# GD32E511_512 register map
File version: 1.0
CPU: CM33 r0p4, little endian, MPU, FPU, 4 interrupt priority bits
Registers are 32-bit, read-write, reset 0x0 unless marked. A register's access mark holds for its fields unless they carry their own. Offsets are from the block's base; [hi:lo] are bit positions; {n}, {i} and the like mark numbered series.

## FWDGT — free watchdog timer
Base 0x40003000
0x00 CTL wo — Control register
  [15:0] CMD — Key value
0x04 PSC — Prescaler register
  [2:0] PSC — Prescaler divider
0x08 RLD reset 0xFFF — Reload register
  [11:0] RLD — Watchdog counter reload value
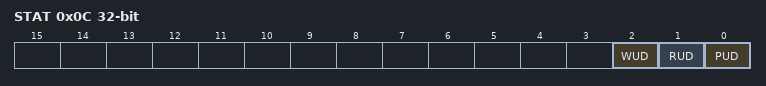
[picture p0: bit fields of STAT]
0x0C STAT ro — Status register
  [2] WUD — Watchdog counter window value update
  [1] RUD — Watchdog counter reload value update
  [0] PUD — Watchdog prescaler value update
0x10 WND reset 0xFFF — Window register
  [11:0] WND — Watchdog counter window value

## GPIOA — General-purpose I / O
Base 0x48000000
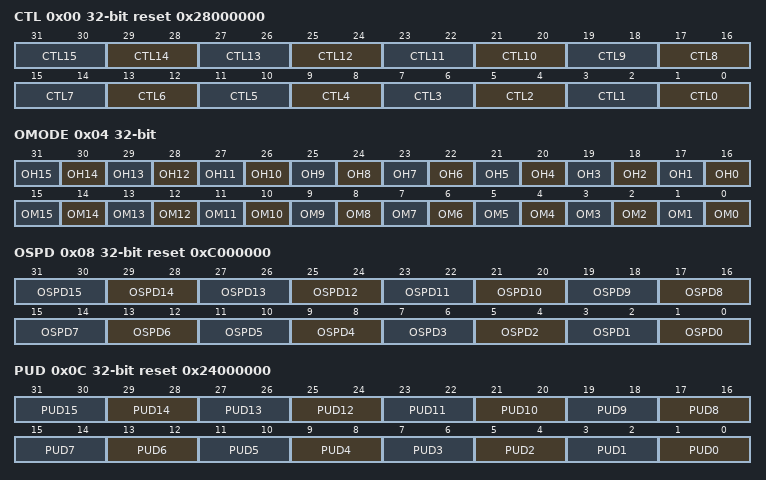
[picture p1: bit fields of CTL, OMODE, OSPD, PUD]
0x00 CTL reset 0x28000000 — Port control register
  [2n+1:2n] CTL{n} (n=0..15) — Pin {n} configuration bits
0x04 OMODE — Port output mode register
  [n+16] OH{n} (n=0..15) — Pin {n} output hold enable bit
  [n] OM{n} (n=0..15) — Pin {n} output mode bit
0x08 OSPD reset 0xC000000 — Port output speed register
  [2n+1:2n] OSPD{n} (n=0..15) — Pin {n} output max speed bits
0x0C PUD reset 0x24000000 — Port pull-up/down register
  [2n+1:2n] PUD{n} (n=0..15) — Pin {n} pull-up or pull-down bits
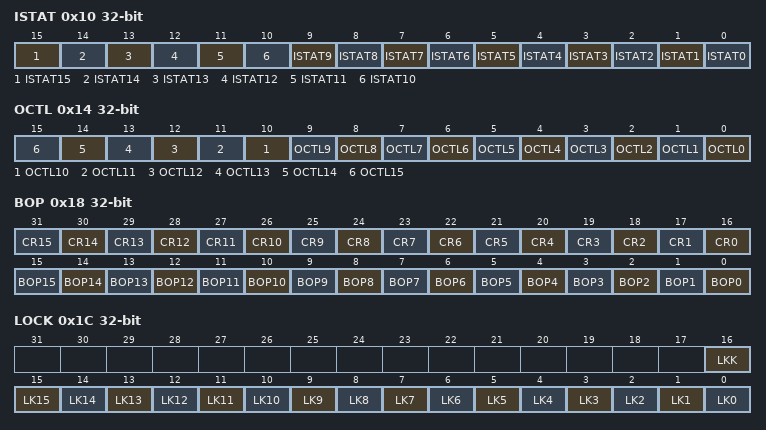
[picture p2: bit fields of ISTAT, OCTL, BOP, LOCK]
0x10 ISTAT ro — Port input status register
  [15] ISTAT15 — Port input status (y=15)
  [14] ISTAT14 — Port input status (y=14)
  [13] ISTAT13 — Port input status (y=13)
  [12] ISTAT12 — Port input status (y=12)
  [11] ISTAT11 — Port input status (y=11)
  [10] ISTAT10 — Port input status (y=10)
  [9] ISTAT9 — Port input status (y=9)
  [8] ISTAT8 — Port input status (y=8)
  [7] ISTAT7 — Port input status (y=7)
  [6] ISTAT6 — Port input status (y=6)
  [5] ISTAT5 — Port input status (y=5)
  [4] ISTAT4 — Port input status (y=4)
  [3] ISTAT3 — Port input status (y=3)
  [2] ISTAT2 — Port input status (y=2)
  [1] ISTAT1 — Port input status (y=1)
  [0] ISTAT0 — Port input status (y=0)
0x14 OCTL — Port output control register
  [n] OCTL{n} (n=0..15) — Port output control {n}
0x18 BOP wo — Port bit operate register
  [n+16] CR{n} (n=0..15) — Port clear bit {n}
  [n] BOP{n} (n=0..15) — Port set bit {n}
0x1C LOCK — Port configuration lock register
  [16] LKK — Lock key
  [n] LK{n} (n=0..15) — Port lock bit {n}
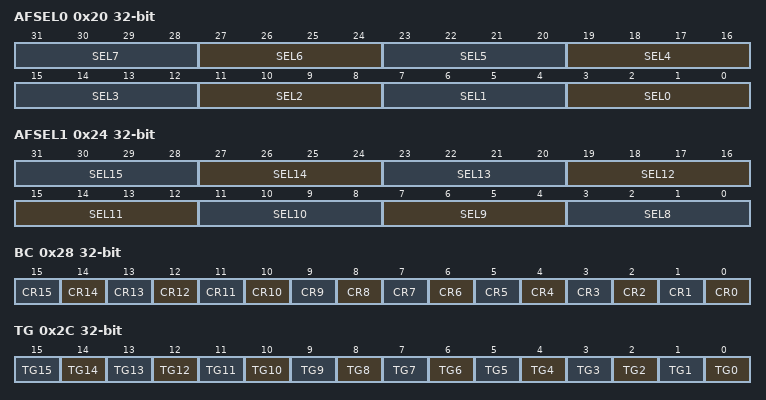
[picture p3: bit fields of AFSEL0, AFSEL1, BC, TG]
0x20 AFSEL0 — Alternate function selected register 0
  [4n+3:4n] SEL{n} (n=0..7) — Pin {n} alternate function selected
0x24 AFSEL1 — Alternate function selected register 1
  [4n-29:4n-32] SEL{n} (n=12..15) — Pin {n} alternate function selected
  [15:12] SEL11 — Pin 1 alternate function selected
  [11:8] SEL10 — Pin 10 alternate function selected
  [7:4] SEL9 — Pin 9 alternate function selected
  [3:0] SEL8 — Pin 8 alternate function selected
0x28 BC wo — Bit clear register
  [n] CR{n} (n=0..15) — Port clear bit {n}
0x2C TG wo — Port bit toggle register
  [n] TG{n} (n=0..15) — Port toggle bit {n}

## GPIOB — General-purpose I / O
Base 0x48000400
Same registers: GPIOC 0x48000800, GPIOD 0x48000C00, GPIOE 0x48001000, GPIOF 0x48001400, GPIOG 0x48001800
Registers as GPIOA; these are added or differ:
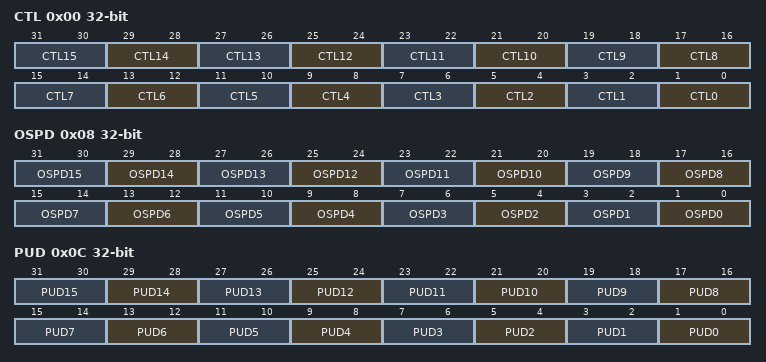
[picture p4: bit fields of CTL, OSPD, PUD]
0x00 CTL — Port control register
  [2n+1:2n] CTL{n} (n=0..15) — Pin {n} configuration bits
0x08 OSPD — Port output speed register
  [2n+1:2n] OSPD{n} (n=0..15) — Pin {n} output max speed bits
0x0C PUD — Port pull-up/down register
  [2n+1:2n] PUD{n} (n=0..15) — Pin {n} pull-up or pull-down bits

## NVIC — Nested Vectored Interrupt Controller
Base 0xE000E100
{0x0+4i} ISER{i} (i=0..15) — Interrupt Set Enable Register
  [31:0] SETENA
0x80 ICER0 — Interrupt Clear Enable Register
  [31:0] CLRENA
0x84 ICER1 — Interrupt Clear Enable Register
  [31:0] CLRENA
{0x84+4i} ICER{i} (i=2..15) — Interrupt Clear Enable Register
  [31:0] CLRENA
{0x100+4i} ISPR{i} (i=0..15) — Interrupt Set-Pending Register
  [31:0] SETPEND
{0x180+4i} ICPR{i} (i=0..15) — Interrupt Clear-Pending Register
  [31:0] CLRPEND
{0x200+4i} IABR{i} (i=0..15) — Interrupt Active bit Register
  [31:0] IABR
{0x280+4i} ITNS{i} (i=0..15) — Interrupt Active bit Register
  [31:0] ITNS
{0x300+i} IPR{i} 8-bit (i=0..31) — Interrupt Priority Register {i}
  [7:0] PRI_{i:02}
